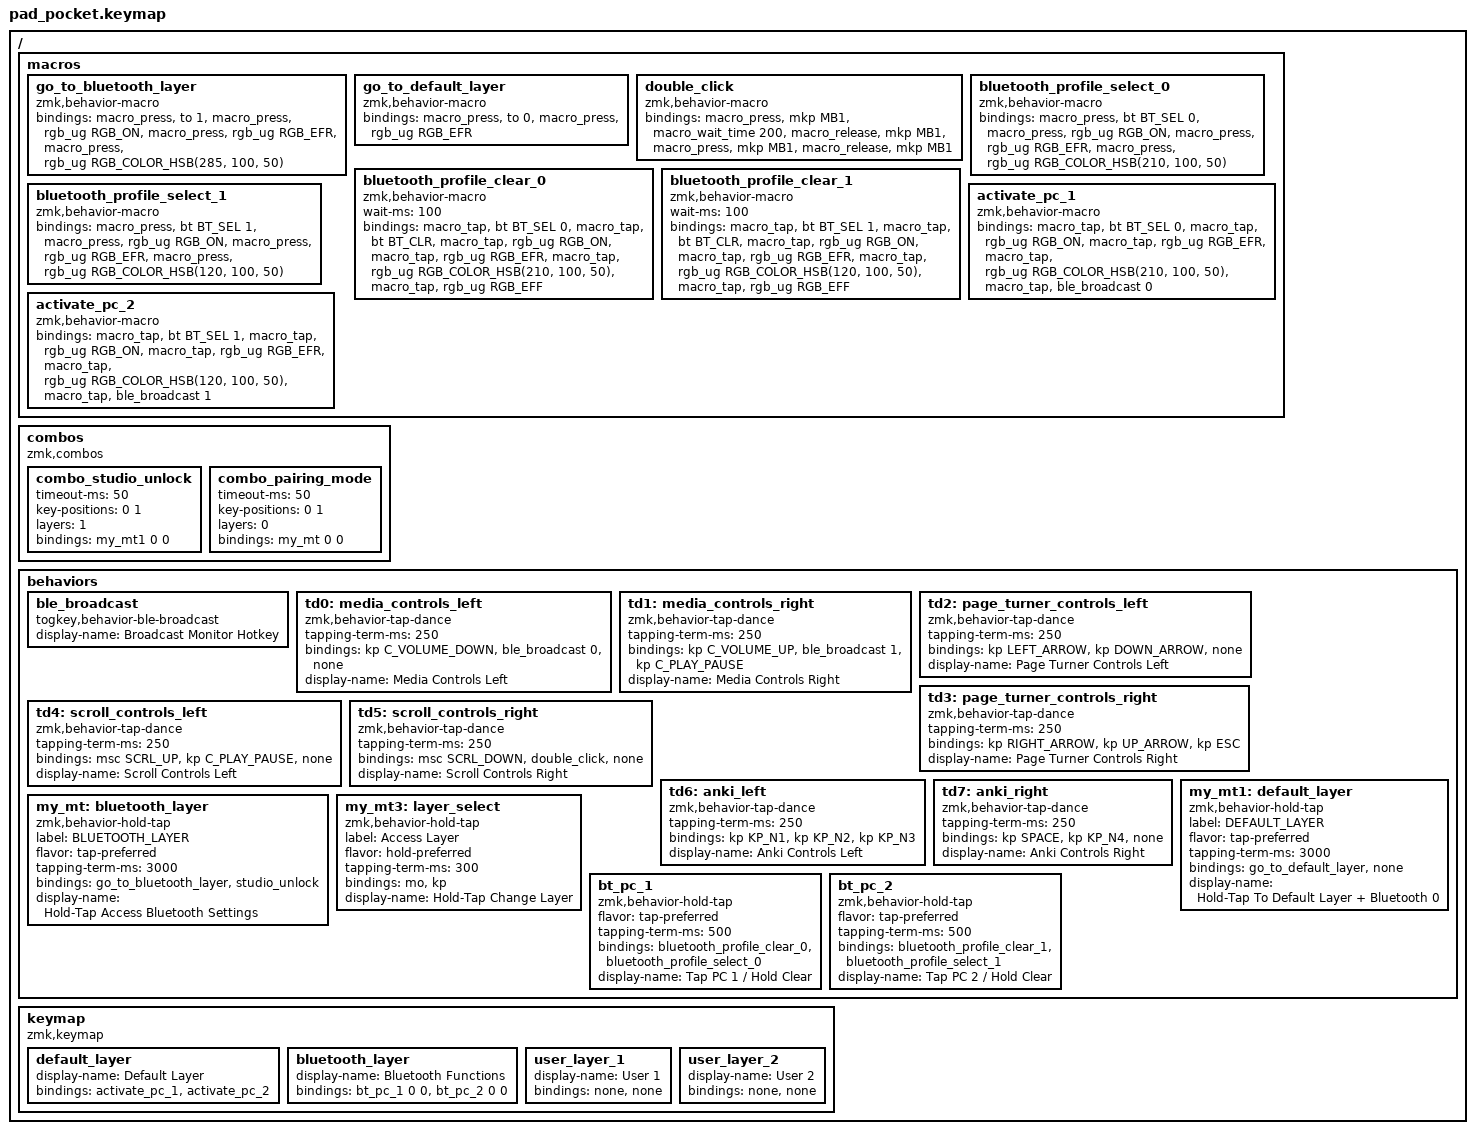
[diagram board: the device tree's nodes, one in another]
#include <behaviors.dtsi>
#include <dt-bindings/zmk/keys.h>
#include <dt-bindings/zmk/bt.h>
#include <dt-bindings/zmk/rgb.h>
#include <dt-bindings/zmk/pointing.h>

/ {
     macros {
        go_to_bluetooth_layer: go_to_bluetooth_layer {
            compatible = "zmk,behavior-macro";
            #binding-cells = <0>;
            // Purple means Bluetooth setup mode.
            bindings = <&macro_press &to 1>
                     , <&macro_press &rgb_ug RGB_ON>
                     , <&macro_press &rgb_ug RGB_EFR>
                     , <&macro_press &rgb_ug RGB_COLOR_HSB(285, 100, 50)>;
        };

        go_to_default_layer: go_to_default_layer {
            compatible = "zmk,behavior-macro";
            #binding-cells = <0>;
            // Keep the selected profile's color, but stop its pairing animation.
            bindings = <&macro_press &to 0>, <&macro_press &rgb_ug RGB_EFR>;
        };

        double_click: double_click {
            compatible = "zmk,behavior-macro";
            #binding-cells = <0>;
            bindings = <&macro_press &mkp MB1>, <&macro_wait_time 200>, <&macro_release &mkp MB1>, <&macro_press &mkp MB1>, <&macro_release &mkp MB1>; 
        };

        bluetooth_profile_select_0: bluetooth_profile_select_0 {
            compatible = "zmk,behavior-macro";
            #binding-cells = <0>;
            // Profile 0 / USB-C is blue.
            bindings = <&macro_press &bt BT_SEL 0>
                     , <&macro_press &rgb_ug RGB_ON>
                     , <&macro_press &rgb_ug RGB_EFR>
                     , <&macro_press &rgb_ug RGB_COLOR_HSB(210, 100, 50)>;
        };

        bluetooth_profile_clear_0: bluetooth_profile_clear_0 {
            compatible = "zmk,behavior-macro";
            #binding-cells = <0>;
            wait-ms = <100>;
            // Breathing blue means profile 0 was cleared and is ready to pair.
            bindings = <&macro_tap &bt BT_SEL 0>
                     , <&macro_tap &bt BT_CLR>
                     , <&macro_tap &rgb_ug RGB_ON>
                     , <&macro_tap &rgb_ug RGB_EFR>
                     , <&macro_tap &rgb_ug RGB_COLOR_HSB(210, 100, 50)>
                     , <&macro_tap &rgb_ug RGB_EFF>;
        };

        bluetooth_profile_clear_1: bluetooth_profile_clear_1 {
            compatible = "zmk,behavior-macro";
            #binding-cells = <0>;
            wait-ms = <100>;
            // Breathing green means profile 1 was cleared and is ready to pair.
            bindings = <&macro_tap &bt BT_SEL 1>
                     , <&macro_tap &bt BT_CLR>
                     , <&macro_tap &rgb_ug RGB_ON>
                     , <&macro_tap &rgb_ug RGB_EFR>
                     , <&macro_tap &rgb_ug RGB_COLOR_HSB(120, 100, 50)>
                     , <&macro_tap &rgb_ug RGB_EFF>;
        };

        bluetooth_profile_select_1: bluetooth_profile_select_1 {
            compatible = "zmk,behavior-macro";
            #binding-cells = <0>;
            // Profile 1 / DisplayPort is green.
            bindings = <&macro_press &bt BT_SEL 1>
                     , <&macro_press &rgb_ug RGB_ON>
                     , <&macro_press &rgb_ug RGB_EFR>
                     , <&macro_press &rgb_ug RGB_COLOR_HSB(120, 100, 50)>;
        };

        activate_pc_1: activate_pc_1 {
            compatible = "zmk,behavior-macro";
            #binding-cells = <0>;
            bindings = <&macro_tap &bt BT_SEL 0>
                     , <&macro_tap &rgb_ug RGB_ON>
                     , <&macro_tap &rgb_ug RGB_EFR>
                     , <&macro_tap &rgb_ug RGB_COLOR_HSB(210, 100, 50)>
                     , <&macro_tap &ble_broadcast 0>;
        };

        activate_pc_2: activate_pc_2 {
            compatible = "zmk,behavior-macro";
            #binding-cells = <0>;
            bindings = <&macro_tap &bt BT_SEL 1>
                     , <&macro_tap &rgb_ug RGB_ON>
                     , <&macro_tap &rgb_ug RGB_EFR>
                     , <&macro_tap &rgb_ug RGB_COLOR_HSB(120, 100, 50)>
                     , <&macro_tap &ble_broadcast 1>;
        };
    };

    combos {
        compatible = "zmk,combos";
        combo_studio_unlock {
            timeout-ms = <50>;
            key-positions = <0 1>;
            layers = <1>;
            bindings = <&my_mt1 0 0>;
        };

        combo_pairing_mode {
            timeout-ms = <50>;
            key-positions = <0 1>;
            layers = <0>;
            bindings = <&my_mt 0 0>;
        };
    };

    behaviors {
        ble_broadcast: ble_broadcast {
            compatible = "togkey,behavior-ble-broadcast";
            #binding-cells = <1>;
            display-name = "Broadcast Monitor Hotkey";
        };

        td0: media_controls_left {
            compatible = "zmk,behavior-tap-dance";
            #binding-cells = <0>;
            tapping-term-ms = <250>;
            bindings = <&kp C_VOLUME_DOWN>, <&ble_broadcast 0>, <&none>;
            display-name = "Media Controls Left";
        };

        td1: media_controls_right {
            compatible = "zmk,behavior-tap-dance";
            #binding-cells = <0>;
            tapping-term-ms = <250>;
            bindings = <&kp C_VOLUME_UP>, <&ble_broadcast 1>, <&kp C_PLAY_PAUSE>;
            display-name = "Media Controls Right";
        };

        td2: page_turner_controls_left {
            compatible = "zmk,behavior-tap-dance";
            #binding-cells = <0>;
            tapping-term-ms = <250>;
            bindings = <&kp LEFT_ARROW>, <&kp DOWN_ARROW>, <&none>;
            display-name = "Page Turner Controls Left";
        };

        td3: page_turner_controls_right {
            compatible = "zmk,behavior-tap-dance";
            #binding-cells = <0>;
            tapping-term-ms = <250>;
            bindings = <&kp RIGHT_ARROW>, <&kp UP_ARROW>, <&kp ESC>;
            display-name = "Page Turner Controls Right";
        };

        td4: scroll_controls_left {
            compatible = "zmk,behavior-tap-dance";
            #binding-cells = <0>;
            tapping-term-ms = <250>;
            bindings = <&msc SCRL_UP>, <&kp C_PLAY_PAUSE>, <&none>;
            display-name = "Scroll Controls Left";
        };

        td5: scroll_controls_right {
            compatible = "zmk,behavior-tap-dance";
            #binding-cells = <0>;
            tapping-term-ms = <250>;
            bindings = <&msc SCRL_DOWN>, <&double_click>, <&none>;
            display-name = "Scroll Controls Right";
        };

        td6: anki_left {
            compatible = "zmk,behavior-tap-dance";
            #binding-cells = <0>;
            tapping-term-ms = <250>;
            bindings = <&kp KP_N1>, <&kp KP_N2>, <&kp KP_N3>;
            display-name = "Anki Controls Left";
        };

        td7: anki_right {
            compatible = "zmk,behavior-tap-dance";
            #binding-cells = <0>;
            tapping-term-ms = <250>;
            bindings = <&kp SPACE>, <&kp KP_N4>, <&none>;
            display-name = "Anki Controls Right";
        };

        my_mt: bluetooth_layer {
            compatible = "zmk,behavior-hold-tap";
            label = "BLUETOOTH_LAYER";
            #binding-cells = <2>;
            flavor = "tap-preferred";
            tapping-term-ms = <3000>;
            bindings = <&go_to_bluetooth_layer>, <&studio_unlock>;
            display-name = "Hold-Tap Access Bluetooth Settings";
        };

        my_mt1: default_layer {
            compatible = "zmk,behavior-hold-tap";
            label = "DEFAULT_LAYER";
            #binding-cells = <2>;
            flavor = "tap-preferred";
            tapping-term-ms = <3000>;
            bindings = <&go_to_default_layer>, <&none>;
            display-name = "Hold-Tap To Default Layer + Bluetooth 0";
        };

        my_mt3: layer_select {
            compatible = "zmk,behavior-hold-tap";
            label = "Access Layer";
            #binding-cells = <2>;
            flavor = "hold-preferred";
            tapping-term-ms = <300>;
            bindings = <&mo>, <&kp>;
            display-name = "Hold-Tap Change Layer";
        };

        bt_pc_1: bt_pc_1 {
            compatible = "zmk,behavior-hold-tap";
            #binding-cells = <2>;
            flavor = "tap-preferred";
            tapping-term-ms = <500>;
            bindings = <&bluetooth_profile_clear_0>, <&bluetooth_profile_select_0>;
            display-name = "Tap PC 1 / Hold Clear";
        };

        bt_pc_2: bt_pc_2 {
            compatible = "zmk,behavior-hold-tap";
            #binding-cells = <2>;
            flavor = "tap-preferred";
            tapping-term-ms = <500>;
            bindings = <&bluetooth_profile_clear_1>, <&bluetooth_profile_select_1>;
            display-name = "Tap PC 2 / Hold Clear";
        };
    };

    keymap {
        compatible = "zmk,keymap";

        default_layer { // Layer 0
            display-name = "Default Layer";
            // -------------------------------------
            //       | PC 1 + USB-C | PC 2 + DP    |
            bindings = <
                &activate_pc_1
                &activate_pc_2
            >;
        };

        bluetooth_layer { // Layer 1
            display-name = "Bluetooth Functions";
            // -------------------------------------
            //       | PC1 tap/clear| PC2 tap/clear|
            bindings = <
                &bt_pc_1 0 0
                &bt_pc_2 0 0
            >;
        };

        user_layer_1 { // Layer 2
            display-name = "User 1";
            // -------------------------------------
            //       |     None     |     None     |
            bindings = <
                &none
                &none
            >;
        };

        user_layer_2 { // Layer 3
            display-name = "User 2";
            // -------------------------------------
            //       |     None     |     None     |
            bindings = <
                &none
                &none
            >;
        };
    };
 };
